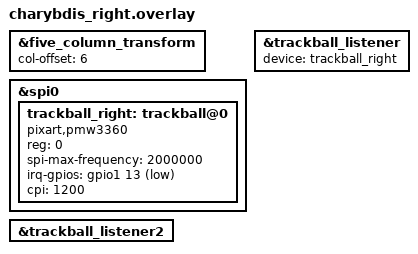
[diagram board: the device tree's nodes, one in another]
#define TRACKBALL_MISO NRF_PSEL(SPIM_MISO, 1, 0)
#include "charybdis_half.dtsi"
#include "charybdis_spi_pinctrl.dtsi"

&five_column_transform {
    col-offset = <6>;
};

&spi0 {
    trackball_right: trackball@0 {
        compatible = "pixart,pmw3360";
        reg = <0>;
        spi-max-frequency = <2000000>;
        irq-gpios = <&gpio1 13 (GPIO_ACTIVE_LOW | GPIO_PULL_UP)>;
        cpi = <1200>;
    };
};

&trackball_listener {
    status = "okay";
    device = <&trackball_right>;
};

&trackball_listener2 {
    status = "okay";
};
